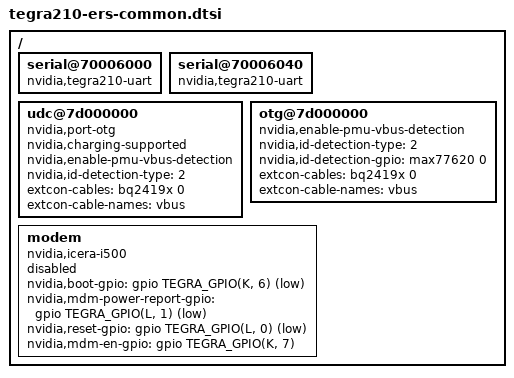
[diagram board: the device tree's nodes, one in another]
/*
 * Copyright (c) 2014, NVIDIA CORPORATION.  All rights reserved.
 *
 * This program is free software; you can redistribute it and/or modify
 * it under the terms of the GNU General Public License as published by
 * the Free Software Foundation; either version 2 of the License, or
 * (at your option) any later version.
 *
 * This program is distributed in the hope that it will be useful, but WITHOUT
 * ANY WARRANTY; without even the implied warranty of MERCHANTABILITY or
 * FITNESS FOR A PARTICULAR PURPOSE.  See the GNU General Public License for
 * more details.
 *
 * You should have received a copy of the GNU General Public License along
 * with this program; if not, write to the Free Software Foundation, Inc.,
 * 51 Franklin Street, Fifth Floor, Boston, MA  02110-1301, USA.
 */

#include "tegra210.dtsi"
#include <dt-bindings/interrupt-controller/arm-gic.h>
#include <dt-bindings/gpio/tegra-gpio.h>
#include "tegra210-platforms/tegra210-ers-dfll-e2174-1101-a00.dtsi"
/ {

	serial@70006000 {
		compatible = "nvidia,tegra210-uart";
		status = "okay";
	};

	serial@70006040 {
		compatible = "nvidia,tegra210-uart";
		status = "okay";
	};

	udc@7d000000 {
		nvidia,port-otg;
		nvidia,charging-supported;
		nvidia,enable-pmu-vbus-detection;
		nvidia,id-detection-type = <2>;
		extcon-cables = <&bq2419x 0>;
		extcon-cable-names = "vbus";
		#extcon-cells = <1>;
		status = "okay";
	};

	otg@7d000000 {
		nvidia,enable-pmu-vbus-detection;
		nvidia,id-detection-type = <2>;
		nvidia,id-detection-gpio = <&max77620 0 0>;
		extcon-cables = <&bq2419x 0>;
		extcon-cable-names = "vbus";
		#extcon-cells = <1>;
		status = "okay";
	};

	modem {
		compatible = "nvidia,icera-i500";
		nvidia,boot-gpio = <&gpio TEGRA_GPIO(K, 6) GPIO_ACTIVE_LOW>;
		nvidia,mdm-power-report-gpio = <&gpio TEGRA_GPIO(L, 1) GPIO_ACTIVE_LOW>;
		nvidia,reset-gpio = <&gpio TEGRA_GPIO(L, 0) GPIO_ACTIVE_LOW>;
		nvidia,mdm-en-gpio = <&gpio TEGRA_GPIO(K, 7) GPIO_ACTIVE_HIGH>;
		status = "disabled";
	};
};
